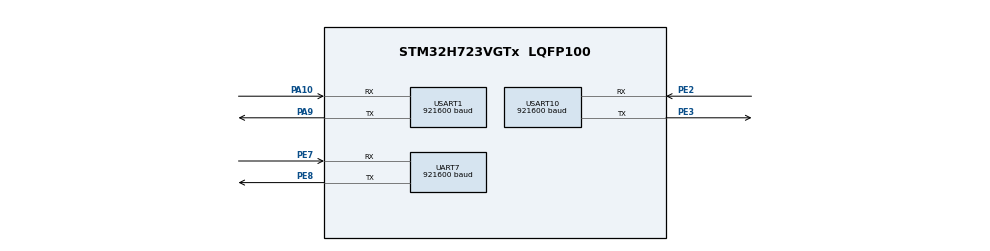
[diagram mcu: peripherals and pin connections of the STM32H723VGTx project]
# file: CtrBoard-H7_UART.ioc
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CORTEX_M7.CPU_DCache=Disabled
CORTEX_M7.CPU_ICache=Disabled
Dma.Request0=USART1_TX
Dma.USART1_TX.0.Direction=DMA_MEMORY_TO_PERIPH
Dma.USART1_TX.0.EventEnable=DISABLE
Dma.USART1_TX.0.FIFOMode=DMA_FIFOMODE_DISABLE
Dma.USART1_TX.0.Instance=DMA1_Stream1
Dma.USART1_TX.0.MemDataAlignment=DMA_MDATAALIGN_BYTE
Dma.USART1_TX.0.MemInc=DMA_MINC_ENABLE
Dma.USART1_TX.0.Mode=DMA_CIRCULAR
Dma.USART1_TX.0.PeriphDataAlignment=DMA_PDATAALIGN_BYTE
Dma.USART1_TX.0.PeriphInc=DMA_PINC_DISABLE
Dma.USART1_TX.0.Polarity=HAL_DMAMUX_REQ_GEN_RISING
Dma.USART1_TX.0.Priority=DMA_PRIORITY_LOW
Dma.USART1_TX.0.RequestNumber=1
Dma.USART1_TX.0.SignalID=NONE
Dma.USART1_TX.0.SyncEnable=DISABLE
Dma.USART1_TX.0.SyncPolarity=HAL_DMAMUX_SYNC_NO_EVENT
Dma.USART1_TX.0.SyncRequestNumber=1
Dma.USART1_TX.0.SyncSignalID=NONE
Mcu.Family=STM32H7
Mcu.Name=STM32H723VGTx
Mcu.Package=LQFP100
NVIC.DMA1_Stream1_IRQn=true\:0\:0\:false\:false\:true\:false\:true\:true
NVIC.PriorityGroup=NVIC_PRIORITYGROUP_4
PA10.Mode=Asynchronous
PA10.Signal=USART1_RX
PA13(JTMS/SWDIO).Mode=Serial_Wire
PA13(JTMS/SWDIO).Signal=DEBUG_JTMS-SWDIO
PA14(JTCK/SWCLK).Mode=Serial_Wire
PA14(JTCK/SWCLK).Signal=DEBUG_JTCK-SWCLK
PA9.Mode=Asynchronous
PA9.Signal=USART1_TX
PE2.Mode=Asynchronous
PE2.Signal=USART10_RX
PE3.Mode=Asynchronous
PE3.Signal=USART10_TX
PE7.Mode=Asynchronous
PE7.Signal=UART7_RX
PE8.Mode=Asynchronous
PE8.Signal=UART7_TX
PH0-OSC_IN.Mode=HSE-External-Oscillator
PH0-OSC_IN.Signal=RCC_OSC_IN
PH1-OSC_OUT.Mode=HSE-External-Oscillator
PH1-OSC_OUT.Signal=RCC_OSC_OUT
ProjectManager.HeapSize=0x200
ProjectManager.StackSize=0x400
ProjectManager.TargetToolchain=MDK-ARM V5.32
RCC.ADCFreq_Value=48375000
RCC.APB1Freq_Value=120000000
RCC.APB2Freq_Value=120000000
RCC.APB3Freq_Value=120000000
RCC.APB4Freq_Value=120000000
RCC.CortexFreq_Value=480000000
RCC.D1PPRE=RCC_APB3_DIV2
RCC.D2PPRE1=RCC_APB1_DIV2
RCC.D2PPRE2=RCC_APB2_DIV2
RCC.D3PPRE=RCC_APB4_DIV2
RCC.DIVM1=2
RCC.DIVN1=40
RCC.DIVP1=1
RCC.DIVQ1=4
RCC.HCLKFreq_Value=240000000
RCC.HPRE=RCC_HCLK_DIV2
RCC.HSE_VALUE=24000000
RCC.PLLFRACN=0
RCC.PLLSourceVirtual=RCC_PLLSOURCE_HSE
RCC.RCC_MCO1Source=RCC_MCO1SOURCE_HSE
RCC.SYSCLKFreq_VALUE=480000000
RCC.SYSCLKSource=RCC_SYSCLKSOURCE_PLLCLK
RCC.USBFreq_Value=120000000
UART7.BaudRate=921600
USART1.BaudRate=921600
USART1.VirtualMode-Asynchronous=VM_ASYNC
USART10.BaudRate=921600
USART10.VirtualMode=VM_ASYNC
board=custom

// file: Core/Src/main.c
/* USER CODE BEGIN Header */
/**
  ******************************************************************************
  * @file           : main.c
  * @brief          : Main program body
  ******************************************************************************
  * @attention
  *
  * Copyright (c) 2024 STMicroelectronics.
  * All rights reserved.
  *
  * This software is licensed under terms that can be found in the LICENSE file
  * in the root directory of this software component.
  * If no LICENSE file comes with this software, it is provided AS-IS.
  *
  ******************************************************************************
  */
/* USER CODE END Header */
#include "main.h"
#include "dma.h"
#include "usart.h"
#include "gpio.h"

void SystemClock_Config(void);

/* USER CODE BEGIN 0 */
uint8_t data[8] = {0x00, 0x01, 0x02, 0x03, 0x04, 0x05, 0x06, 0x07};
/* USER CODE END 0 */

int main(void)
{

  /* MCU Configuration--------------------------------------------------------*/

  /* Reset of all peripherals, Initializes the Flash interface and the Systick. */
  HAL_Init();

  /* Configure the system clock */
  SystemClock_Config();

  /* Initialize all configured peripherals */
  MX_GPIO_Init();
  MX_DMA_Init();
  MX_USART1_UART_Init();
  MX_USART10_UART_Init();
  MX_UART7_Init();

  /* Infinite loop */
  /* USER CODE BEGIN WHILE */
  while (1)
  {
		HAL_UART_Transmit(&huart1, 	data, 8, 0xffff);
		HAL_UART_Transmit(&huart7, 	data, 8, 0xffff);
		HAL_UART_Transmit(&huart10, data, 8, 0xffff);

		HAL_Delay(500);
    /* USER CODE END WHILE */

  }
}

void SystemClock_Config(void)
{
  RCC_OscInitTypeDef RCC_OscInitStruct = {0};
  RCC_ClkInitTypeDef RCC_ClkInitStruct = {0};

  /** Supply configuration update enable
  */
  HAL_PWREx_ConfigSupply(PWR_LDO_SUPPLY);

  /** Configure the main internal regulator output voltage
  */
  __HAL_PWR_VOLTAGESCALING_CONFIG(PWR_REGULATOR_VOLTAGE_SCALE0);

  while(!__HAL_PWR_GET_FLAG(PWR_FLAG_VOSRDY)) {}

  /** Initializes the RCC Oscillators according to the specified parameters
  * in the RCC_OscInitTypeDef structure.
  */
  RCC_OscInitStruct.OscillatorType = RCC_OSCILLATORTYPE_HSE;
  RCC_OscInitStruct.HSEState = RCC_HSE_ON;
  RCC_OscInitStruct.PLL.PLLState = RCC_PLL_ON;
  RCC_OscInitStruct.PLL.PLLSource = RCC_PLLSOURCE_HSE;
  RCC_OscInitStruct.PLL.PLLM = 2;
  RCC_OscInitStruct.PLL.PLLN = 40;
  RCC_OscInitStruct.PLL.PLLP = 1;
  RCC_OscInitStruct.PLL.PLLQ = 4;
  RCC_OscInitStruct.PLL.PLLR = 2;
  RCC_OscInitStruct.PLL.PLLRGE = RCC_PLL1VCIRANGE_3;
  RCC_OscInitStruct.PLL.PLLVCOSEL = RCC_PLL1VCOWIDE;
  RCC_OscInitStruct.PLL.PLLFRACN = 0;
  if (HAL_RCC_OscConfig(&RCC_OscInitStruct) != HAL_OK)
  {
    Error_Handler();
  }

  /** Initializes the CPU, AHB and APB buses clocks
  */
  RCC_ClkInitStruct.ClockType = RCC_CLOCKTYPE_HCLK|RCC_CLOCKTYPE_SYSCLK
                              |RCC_CLOCKTYPE_PCLK1|RCC_CLOCKTYPE_PCLK2
                              |RCC_CLOCKTYPE_D3PCLK1|RCC_CLOCKTYPE_D1PCLK1;
  RCC_ClkInitStruct.SYSCLKSource = RCC_SYSCLKSOURCE_PLLCLK;
  RCC_ClkInitStruct.SYSCLKDivider = RCC_SYSCLK_DIV1;
  RCC_ClkInitStruct.AHBCLKDivider = RCC_HCLK_DIV2;
  RCC_ClkInitStruct.APB3CLKDivider = RCC_APB3_DIV2;
  RCC_ClkInitStruct.APB1CLKDivider = RCC_APB1_DIV2;
  RCC_ClkInitStruct.APB2CLKDivider = RCC_APB2_DIV2;
  RCC_ClkInitStruct.APB4CLKDivider = RCC_APB4_DIV2;

  if (HAL_RCC_ClockConfig(&RCC_ClkInitStruct, FLASH_LATENCY_3) != HAL_OK)
  {
    Error_Handler();
  }
}

void Error_Handler(void)
{
  __disable_irq();
  while (1)
  {
  }
}
